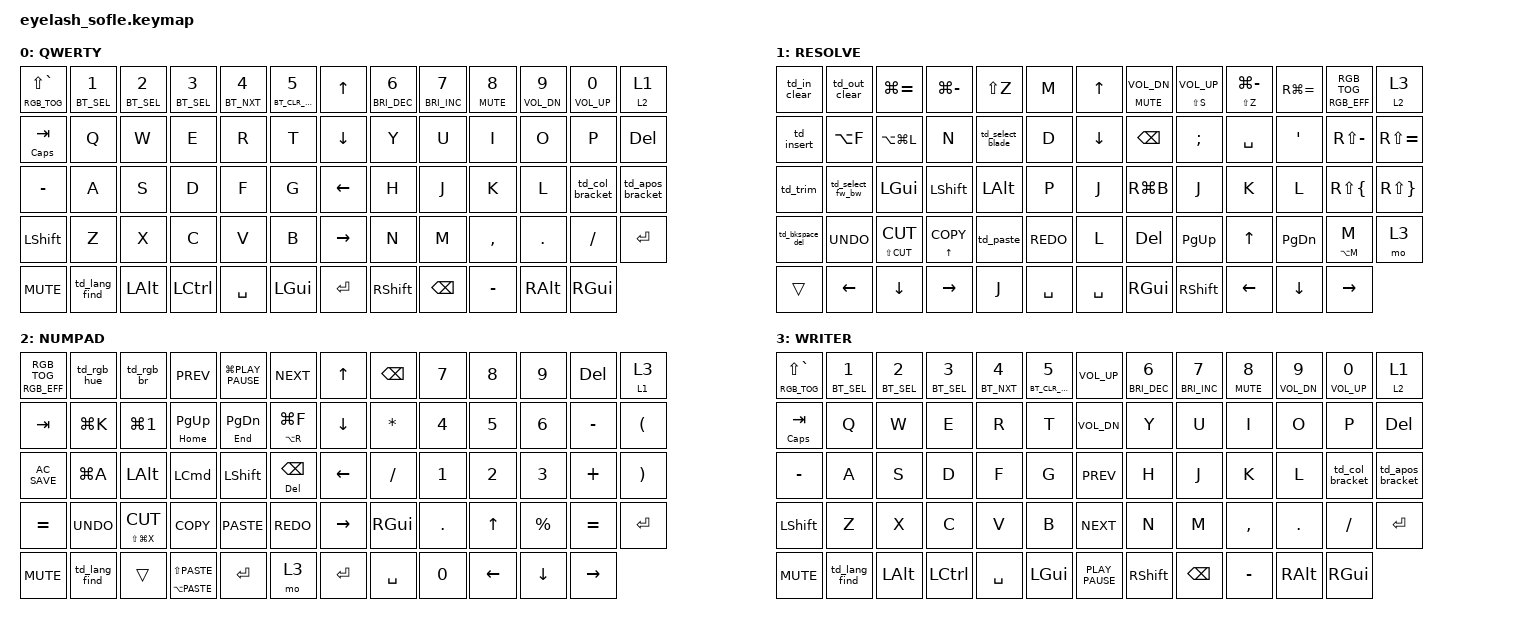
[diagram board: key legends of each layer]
#define ZMK_POINTING_DEFAULT_MOVE_VAL 1200  // 600
#define ZMK_POINTING_DEFAULT_SCRL_VAL 25   // 10

#include <input/processors.dtsi>
#include <zephyr/dt-bindings/input/input-event-codes.h>
#include <behaviors.dtsi>
#include <dt-bindings/zmk/bt.h>
#include <dt-bindings/zmk/keys.h>
#include <dt-bindings/zmk/pointing.h>
#include <dt-bindings/zmk/rgb.h>

&mmv_input_listener { input-processors = <&zip_xy_scaler 2 1>; };

&msc_input_listener { input-processors = <&zip_scroll_scaler 2 1>; };

&msc {
    acceleration-exponent = <1>;      // 0
    time-to-max-speed-ms = <100>;       // 300
    delay-ms = <0>;                   // 0
};

&mmv {
    time-to-max-speed-ms = <500>;
    acceleration-exponent = <1>;
    trigger-period-ms = <16>;
};

/ {
    scroll_encoder: scroll_encoder {
        compatible = "zmk,behavior-sensor-rotate";
        #sensor-binding-cells = <0>;
        bindings = <&msc SCRL_DOWN>, <&msc SCRL_UP>;

        tap-ms = <100>;
    };

    td_in_clear: td_in_clear {
        compatible = "zmk,behavior-tap-dance";
        label = "TD_IN_CLEAR";
        #binding-cells = <0>;
        bindings = <&kp I>, <&kp LA(X)>;
    };

    ht_bt: ht_bt {
        compatible = "zmk,behavior-hold-tap";
        label = "HT_BT";
        bindings = <&bt>, <&kp>;

        #binding-cells = <2>;
        tapping-term-ms = <200>;
        flavor = "balanced";
    };

    ht_rgb: ht_rgb {
        compatible = "zmk,behavior-hold-tap";
        label = "HT_RGB";
        bindings = <&rgb_ug>, <&rgb_ug>;

        #binding-cells = <2>;
        tapping-term-ms = <200>;
        flavor = "balanced";
    };

    ht_mt: ht_mt {
        compatible = "zmk,behavior-hold-tap";
        label = "HT_MT";
        bindings = <&kp>, <&kp>;

        #binding-cells = <2>;
        tapping-term-ms = <200>;
        flavor = "balanced";
    };

    td_out_clear: td_out_clear {
        compatible = "zmk,behavior-tap-dance";
        label = "TD_OUT_CLEAR";
        #binding-cells = <0>;
        bindings = <&kp O>, <&kp LA(X)>;
    };

    td_select_clear: td_select_clear {
        compatible = "zmk,behavior-tap-dance";
        label = "TD_SELECT_CLEAR";
        #binding-cells = <0>;
        bindings = <&kp X>, <&kp RA(X)>;
    };

    td_select_blade: td_select_blade {
        compatible = "zmk,behavior-tap-dance";
        label = "TD_SELECT_BLADE";
        #binding-cells = <0>;
        bindings = <&kp A>, <&kp B>;
    };

    td_bkspace_del: td_bkspace_del {
        compatible = "zmk,behavior-tap-dance";
        label = "TD_BKSPACE_DEL";
        #binding-cells = <0>;
        bindings = <&kp BACKSPACE>, <&kp DELETE>;
    };

    td_insert: td_insert {
        compatible = "zmk,behavior-tap-dance";
        label = "TD_INSERT";
        #binding-cells = <0>;
        bindings = <&kp F9>, <&kp F10>, <&kp F11>;
    };

    td_trim: td_trim {
        compatible = "zmk,behavior-tap-dance";
        label = "TD_TRIM";
        #binding-cells = <0>;
        bindings = <&kp T>, <&kp W>;
    };

    td_select_fw_bw: td_select_fw_bw {
        compatible = "zmk,behavior-tap-dance";
        label = "TD_SELECT_FW_BW";
        #binding-cells = <0>;
        bindings = <&kp LA(Y)>, <&kp LG(Y)>;
    };

    ht_mkp: ht_mkp {
        compatible = "zmk,behavior-hold-tap";
        label = "HT_MKP";
        bindings = <&mkp>, <&mkp>;

        #binding-cells = <2>;
        tapping-term-ms = <200>;
        flavor = "balanced";
    };

    td_paste: td_paste {
        compatible = "zmk,behavior-tap-dance";
        label = "TD_PASTE";
        #binding-cells = <0>;
        bindings = <&kp K_PASTE>, <&kp RS(K_PASTE)>, <&kp LA(V)>;
    };

    ht_toggle: ht_toggle {
        compatible = "zmk,behavior-hold-tap";
        label = "HT_TOGGLE";
        bindings = <&tog>, <&tog>;

        #binding-cells = <2>;
        tapping-term-ms = <200>;
    };

    ht_rgb_2: ht_rgb_2 {
        compatible = "zmk,behavior-hold-tap";
        label = "HT_RGB_2";
        bindings = <&rgb_ug>, <&kp>;

        #binding-cells = <2>;
        tapping-term-ms = <200>;
        flavor = "balanced";
    };

    td_lang_find: td_lang_find {
        compatible = "zmk,behavior-tap-dance";
        label = "TD_LANG_FIND";
        #binding-cells = <0>;
        bindings = <&kp LG(SPACE)>, <&kp LC(SPACE)>;
    };

    td_rgb_hue: td_rgb_hue {
        compatible = "zmk,behavior-tap-dance";
        label = "TD_RGB_HUE";
        #binding-cells = <0>;
        bindings =
            <&rgb_ug RGB_HUI>,
            <&rgb_ug RGB_HUD>,
            <&rgb_ug RGB_COLOR_HSB(0,0,100)>,
            <&rgb_ug RGB_COLOR_HSB(264,93,75)>;
    };

    td_rgb_br: td_rgb_br {
        compatible = "zmk,behavior-tap-dance";
        label = "TD_RGB_BR";
        #binding-cells = <0>;
        bindings = <&rgb_ug RGB_BRI>, <&rgb_ug RGB_BRD>;
    };

    td_col_bracket: td_col_bracket {
        compatible = "zmk,behavior-tap-dance";
        label = "TD_COL_BRACKET";
        #binding-cells = <0>;
        bindings = <&kp SEMICOLON>, <&kp LEFT_BRACKET>;
    };

    td_apos_bracket: td_apos_bracket {
        compatible = "zmk,behavior-tap-dance";
        label = "TD_APOS_BRACKET";
        #binding-cells = <0>;
        bindings = <&kp SQT>, <&kp RIGHT_BRACKET>, <&kp BACKSLASH>;
    };

    behaviors {
    };

    keymap {
        compatible = "zmk,keymap";

        layer_0 {
            display-name = "QWERTY";
            bindings = <
&ht_rgb_2 RGB_TOG LS(GRAVE)  &ht_bt BT_SEL N1 0  &ht_bt BT_SEL N2 1  &ht_bt BT_SEL N3 2  &ht_bt BT_NXT N4  &ht_bt BT_CLR_ALL N5    &kp UP_ARROW  &ht_mt C_BRIGHTNESS_DEC N6  &ht_mt C_BRIGHTNESS_INC N7  &ht_mt K_MUTE N8  &ht_mt C_VOL_DN N9  &ht_mt C_VOL_UP N0  &ht_toggle 2 1
&ht_mt CAPS TAB              &kp Q               &kp W               &kp E               &kp R             &kp T                   &kp DOWN      &kp Y                       &kp U                       &kp I             &kp O               &kp P               &kp DEL
&kp MINUS                    &kp A               &kp S               &kp D               &kp F             &kp G                   &kp LEFT      &kp H                       &kp J                       &kp K             &kp L               &td_col_bracket     &td_apos_bracket
&kp LSHFT                    &kp Z               &kp X               &kp C               &kp V             &kp B                   &kp RIGHT     &kp N                       &kp M                       &kp COMMA         &kp DOT             &kp FSLH            &kp ENTER
&kp C_MUTE                   &td_lang_find       &kp LEFT_ALT        &kp LCTRL           &kp SPACE         &kp LEFT_GUI            &kp ENTER     &kp RIGHT_SHIFT             &kp BACKSPACE               &kp MINUS         &kp RIGHT_ALT       &kp RIGHT_GUI
            >;

            sensor-bindings = <&inc_dec_kp C_VOLUME_UP C_VOL_DN>;
        };

        layer_1 {
            bindings = <
&td_in_clear     &td_out_clear     &kp LG(EQUAL)           &kp LG(MINUS)           &kp LS(Z)         &kp M         &kp UP     &ht_mt K_MUTE C_VOL_DN  &ht_mt LS(S) C_VOL_UP  &ht_mt LS(Z) LG(MINUS)  &kp RG(EQUAL)  &ht_rgb RGB_EFF RGB_TOG  &ht_toggle 2 3
&td_insert       &kp LA(F)         &kp LA(LG(L))           &kp N                   &td_select_blade  &kp D         &kp DOWN   &kp BACKSPACE           &kp SEMI               &kp SPACE               &kp SQT        &kp RS(MINUS)            &kp RS(EQUAL)
&td_trim         &td_select_fw_bw  &kp LGUI                &kp LSHIFT              &kp LEFT_ALT      &kp P         &kp J      &kp RG(B)               &kp J                  &kp K                   &kp L          &kp RS(LBRC)             &kp RS(RBRC)
&td_bkspace_del  &kp K_UNDO        &ht_mt LS(K_CUT) K_CUT  &ht_mt UP_ARROW K_COPY  &td_paste         &kp K_REDO    &kp L      &kp DELETE              &kp PG_UP              &kp UP_ARROW            &kp PG_DN      &ht_mt LA(M) M           &mo 3
&trans           &kp LEFT          &kp DOWN                &kp RIGHT               &kp J             &kp SPACE     &kp SPACE  &kp RIGHT_GUI           &kp RSHIFT             &kp LEFT                &kp DOWN       &kp RIGHT
            >;

            sensor-bindings = <&scroll_encoder>;
            label = "RESOLVE";
        };

        layer_2 {
            bindings = <
&ht_rgb RGB_EFF RGB_TOG  &td_rgb_hue    &td_rgb_br              &kp K_PREV                      &kp LG(K_PLAY_PAUSE)  &kp K_NEXT              &kp UP     &kp BACKSPACE  &kp N7   &kp N8    &kp N9     &kp DEL    &ht_toggle 1 3
&kp TAB                  &kp LG(K)      &kp LG(N1)              &ht_mt HOME PG_UP               &ht_mt END PG_DN      &ht_mt LA(R) LG(F)      &kp DOWN   &kp ASTERISK   &kp N4   &kp N5    &kp N6     &kp MINUS  &kp LPAR
&kp C_AC_SAVE            &kp LG(A)      &kp LEFT_ALT            &kp LCMD                        &kp LEFT_SHIFT        &ht_mt DEL BACKSPACE    &kp LEFT   &kp SLASH      &kp N1   &kp N2    &kp N3     &kp PLUS   &kp RPAR
&kp EQUAL                &kp K_UNDO     &ht_mt LS(LG(X)) K_CUT  &kp K_COPY                      &kp K_PASTE           &kp K_REDO              &kp RIGHT  &kp RGUI       &kp DOT  &kp UP    &kp PRCNT  &kp EQUAL  &kp RETURN
&kp C_MUTE               &td_lang_find  &trans                  &ht_mt LA(K_PASTE) LS(K_PASTE)  &kp ENTER             &mo 3                   &kp ENTER  &kp SPACE      &kp N0   &kp LEFT  &kp DOWN   &kp RIGHT
            >;

            display-name = "NUMPAD";
            sensor-bindings = <&scroll_encoder>;
        };

        layer_3 {
            bindings = <
&ht_rgb_2 RGB_TOG LS(GRAVE)  &ht_bt BT_SEL N1 0  &ht_bt BT_SEL N2 1  &ht_bt BT_SEL N3 2  &ht_bt BT_NXT N4  &ht_bt BT_CLR_ALL N5    &kp C_VOL_UP      &ht_mt C_BRIGHTNESS_DEC N6  &ht_mt C_BRIGHTNESS_INC N7  &ht_mt K_MUTE N8  &ht_mt C_VOL_DN N9  &ht_mt C_VOL_UP N0  &ht_toggle 2 1
&ht_mt CAPS TAB              &kp Q               &kp W               &kp E               &kp R             &kp T                   &kp C_VOL_DN      &kp Y                       &kp U                       &kp I             &kp O               &kp P               &kp DEL
&kp MINUS                    &kp A               &kp S               &kp D               &kp F             &kp G                   &kp K_PREV        &kp H                       &kp J                       &kp K             &kp L               &td_col_bracket     &td_apos_bracket
&kp LSHFT                    &kp Z               &kp X               &kp C               &kp V             &kp B                   &kp K_NEXT        &kp N                       &kp M                       &kp COMMA         &kp DOT             &kp FSLH            &kp ENTER
&kp C_MUTE                   &td_lang_find       &kp LEFT_ALT        &kp LCTRL           &kp SPACE         &kp LEFT_GUI            &kp K_PLAY_PAUSE  &kp RIGHT_SHIFT             &kp BACKSPACE               &kp MINUS         &kp RIGHT_ALT       &kp RIGHT_GUI
            >;

            sensor-bindings = <&inc_dec_kp C_VOLUME_UP C_VOL_DN>;
            display-name = "WRITER";
        };
    };
};
